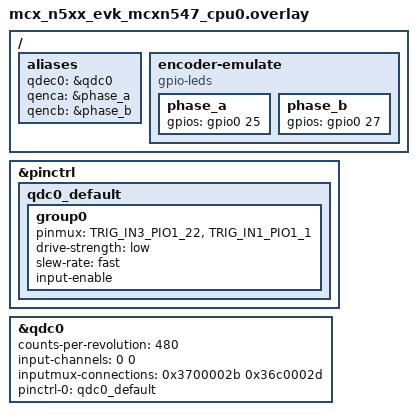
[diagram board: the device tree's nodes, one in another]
/*
 * Copyright 2026 NXP
 *
 * SPDX-License-Identifier: Apache-2.0
 */

#include <zephyr/dt-bindings/gpio/gpio.h>

/ {
	aliases {
		qdec0 = &qdc0;
		qenca = &phase_a;
		qencb = &phase_b;
	};

	encoder-emulate {
		compatible = "gpio-leds";

		phase_a: phase_a {
			gpios = <&gpio0 25 GPIO_ACTIVE_HIGH>;
			status = "okay";
		};

		phase_b: phase_b {
			gpios = <&gpio0 27 GPIO_ACTIVE_HIGH>;
			status = "okay";
		};
	};
};

/* Connect J19 3 -> J3 3, J19 4 -> J2 15 */
&pinctrl {
	qdc0_default: qdc0_default {
		group0 {
			pinmux = <TRIG_IN3_PIO1_22>,
				 <TRIG_IN1_PIO1_1>;
			drive-strength = "low";
			slew-rate = "fast";
			input-enable;
		};
	};
};

&qdc0 {
	status = "okay";
	counts-per-revolution = <480>;
	input-channels = <0 0>;
	inputmux-connections = <0x3700002b 0x36c0002d>;
	pinctrl-0 = <&qdc0_default>;
	pinctrl-names = "default";
};
